AUTOSAR XML (schema 4-2-2)
package /Components
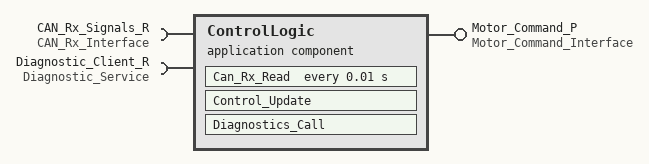
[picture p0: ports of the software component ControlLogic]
  application sw component type ControlLogic
    provide port Motor_Command_P: provided-interface=Motor_Command_Interface
    require port CAN_Rx_Signals_R: required-interface=CAN_Rx_Interface
    require port Diagnostic_Client_R: required-interface=Diagnostic_Service
    behavior ControlLogicBehavior
      data received event New_CAN_Signals: start-on-event=Can_Message_Parse
      timing event ControlCycle_10ms: start-on-event=Can_Rx_Read, period=0.01
      runnable Control_Update: minimum-start-interval=0.01, symbol=Control_UpdateRunnable
        data-receive-point-by-values:
          access Read_Position: accessed-variable=CAN_Rx_Signals_R.position
          access Read_Speed: accessed-variable=CAN_Rx_Signals_R.speed
          access Read_ControlMode: accessed-variable=CAN_Rx_Signals_R.control_mode
        data-send-points:
          access Write_Motor1_Cmd: accessed-variable=Motor_Command_P.motor1_cmd
          access Write_Motor2_Cmd: accessed-variable=Motor_Command_P.motor2_cmd
          access Write_Enable: accessed-variable=Motor_Command_P.enable
        parameter access PID_Gains: accessed-parameter=PID_Params_P.Kp
      runnable Diagnostics_Call: minimum-start-interval=1, symbol=Diagnostics_CallRunnable
        sync call Call_GetStatus: operation=Diagnostic_Client_R.GetStatus, timeout=50
